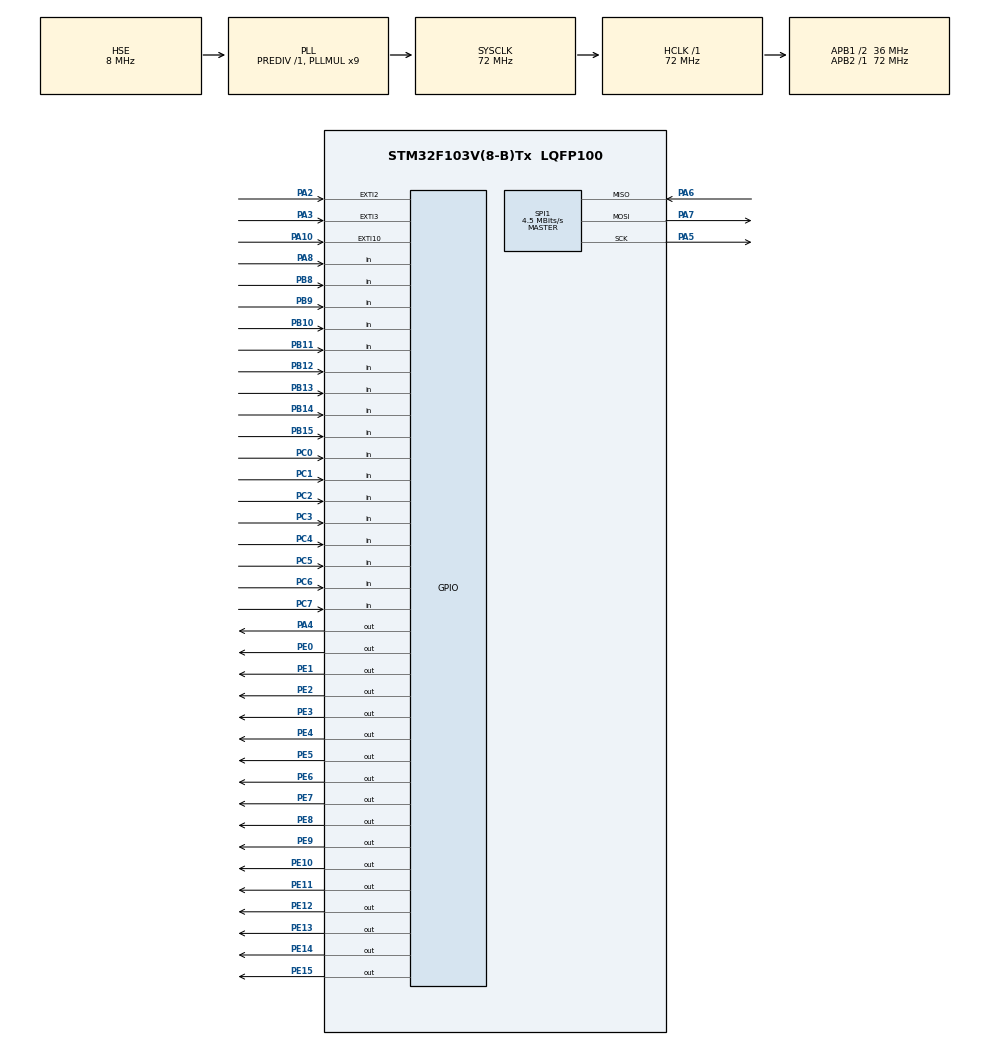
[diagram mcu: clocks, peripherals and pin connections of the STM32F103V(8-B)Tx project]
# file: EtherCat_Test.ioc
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Mcu.Family=STM32F1
Mcu.Name=STM32F103V(8-B)Tx
Mcu.Package=LQFP100
NVIC.EXTI15_10_IRQn=true\:0\:0\:false\:false\:true\:true\:true\:true
NVIC.EXTI2_IRQn=true\:0\:0\:false\:false\:true\:true\:true\:true
NVIC.EXTI3_IRQn=true\:0\:0\:false\:false\:true\:true\:true\:true
NVIC.PriorityGroup=NVIC_PRIORITYGROUP_4
OSC_IN.Mode=HSE-External-Oscillator
OSC_IN.Signal=RCC_OSC_IN
OSC_OUT.Mode=HSE-External-Oscillator
OSC_OUT.Signal=RCC_OSC_OUT
PA10.Signal=GPXTI10
PA13.Mode=Serial_Wire
PA13.Signal=SYS_JTMS-SWDIO
PA14.Mode=Serial_Wire
PA14.Signal=SYS_JTCK-SWCLK
PA2.Signal=GPXTI2
PA3.Signal=GPXTI3
PA4.Signal=GPIO_Output
PA5.Mode=Full_Duplex_Master
PA5.Signal=SPI1_SCK
PA6.Mode=Full_Duplex_Master
PA6.Signal=SPI1_MISO
PA7.Mode=Full_Duplex_Master
PA7.Signal=SPI1_MOSI
PA8.Signal=GPIO_Input
PB10.GPIO_Mode=GPIO_MODE_INPUT
PB10.GPIO_PuPd=GPIO_PULLDOWN
PB10.Signal=GPIO_Input
PB11.GPIO_Mode=GPIO_MODE_INPUT
PB11.GPIO_PuPd=GPIO_PULLDOWN
PB11.Signal=GPIO_Input
PB12.GPIO_Mode=GPIO_MODE_INPUT
PB12.GPIO_PuPd=GPIO_PULLDOWN
PB12.Signal=GPIO_Input
PB13.GPIO_Mode=GPIO_MODE_INPUT
PB13.GPIO_PuPd=GPIO_PULLDOWN
PB13.Signal=GPIO_Input
PB14.GPIO_Mode=GPIO_MODE_INPUT
PB14.GPIO_PuPd=GPIO_PULLDOWN
PB14.Signal=GPIO_Input
PB15.GPIO_Mode=GPIO_MODE_INPUT
PB15.GPIO_PuPd=GPIO_PULLDOWN
PB15.Signal=GPIO_Input
PB8.GPIO_Mode=GPIO_MODE_INPUT
PB8.GPIO_PuPd=GPIO_PULLDOWN
PB8.Signal=GPIO_Input
PB9.GPIO_Mode=GPIO_MODE_INPUT
PB9.GPIO_PuPd=GPIO_PULLDOWN
PB9.Signal=GPIO_Input
PC0.GPIO_Mode=GPIO_MODE_INPUT
PC0.GPIO_PuPd=GPIO_PULLDOWN
PC0.Signal=GPIO_Input
PC1.GPIO_Mode=GPIO_MODE_INPUT
PC1.GPIO_PuPd=GPIO_PULLDOWN
PC1.Signal=GPIO_Input
PC14-OSC32_IN.Mode=LSE-External-Oscillator
PC14-OSC32_IN.Signal=RCC_OSC32_IN
PC15-OSC32_OUT.Mode=LSE-External-Oscillator
PC15-OSC32_OUT.Signal=RCC_OSC32_OUT
PC2.GPIO_Mode=GPIO_MODE_INPUT
PC2.GPIO_PuPd=GPIO_PULLDOWN
PC2.Signal=GPIO_Input
PC3.GPIO_Mode=GPIO_MODE_INPUT
PC3.GPIO_PuPd=GPIO_PULLDOWN
PC3.Signal=GPIO_Input
PC4.GPIO_Mode=GPIO_MODE_INPUT
PC4.GPIO_PuPd=GPIO_PULLDOWN
PC4.Signal=GPIO_Input
PC5.GPIO_Mode=GPIO_MODE_INPUT
PC5.GPIO_PuPd=GPIO_PULLDOWN
PC5.Signal=GPIO_Input
PC6.GPIO_Mode=GPIO_MODE_INPUT
PC6.GPIO_PuPd=GPIO_PULLDOWN
PC6.Signal=GPIO_Input
PC7.GPIO_Mode=GPIO_MODE_INPUT
PC7.GPIO_PuPd=GPIO_PULLDOWN
PC7.Signal=GPIO_Input
PE0.GPIO_ModeDefaultOutputPP=GPIO_MODE_OUTPUT_PP
PE0.GPIO_PuPd=GPIO_NOPULL
PE0.GPIO_Speed=GPIO_SPEED_FREQ_LOW
PE0.PinState=GPIO_PIN_RESET
PE0.Signal=GPIO_Output
PE1.GPIO_ModeDefaultOutputPP=GPIO_MODE_OUTPUT_PP
PE1.GPIO_PuPd=GPIO_NOPULL
PE1.GPIO_Speed=GPIO_SPEED_FREQ_LOW
PE1.PinState=GPIO_PIN_RESET
PE1.Signal=GPIO_Output
PE10.GPIO_ModeDefaultOutputPP=GPIO_MODE_OUTPUT_PP
PE10.GPIO_PuPd=GPIO_NOPULL
PE10.GPIO_Speed=GPIO_SPEED_FREQ_LOW
PE10.PinState=GPIO_PIN_RESET
PE10.Signal=GPIO_Output
PE11.GPIO_ModeDefaultOutputPP=GPIO_MODE_OUTPUT_PP
PE11.GPIO_PuPd=GPIO_NOPULL
PE11.GPIO_Speed=GPIO_SPEED_FREQ_LOW
PE11.PinState=GPIO_PIN_RESET
PE11.Signal=GPIO_Output
PE12.GPIO_ModeDefaultOutputPP=GPIO_MODE_OUTPUT_PP
PE12.GPIO_PuPd=GPIO_NOPULL
PE12.GPIO_Speed=GPIO_SPEED_FREQ_LOW
PE12.PinState=GPIO_PIN_RESET
PE12.Signal=GPIO_Output
PE13.GPIO_ModeDefaultOutputPP=GPIO_MODE_OUTPUT_PP
PE13.GPIO_PuPd=GPIO_NOPULL
PE13.GPIO_Speed=GPIO_SPEED_FREQ_LOW
PE13.PinState=GPIO_PIN_RESET
PE13.Signal=GPIO_Output
PE14.GPIO_ModeDefaultOutputPP=GPIO_MODE_OUTPUT_PP
PE14.GPIO_PuPd=GPIO_NOPULL
PE14.GPIO_Speed=GPIO_SPEED_FREQ_LOW
PE14.PinState=GPIO_PIN_RESET
PE14.Signal=GPIO_Output
PE15.GPIO_ModeDefaultOutputPP=GPIO_MODE_OUTPUT_PP
PE15.GPIO_PuPd=GPIO_NOPULL
PE15.GPIO_Speed=GPIO_SPEED_FREQ_LOW
PE15.PinState=GPIO_PIN_RESET
PE15.Signal=GPIO_Output
PE2.GPIO_ModeDefaultOutputPP=GPIO_MODE_OUTPUT_PP
PE2.GPIO_PuPd=GPIO_NOPULL
PE2.GPIO_Speed=GPIO_SPEED_FREQ_LOW
PE2.PinState=GPIO_PIN_RESET
PE2.Signal=GPIO_Output
PE3.GPIO_ModeDefaultOutputPP=GPIO_MODE_OUTPUT_PP
PE3.GPIO_PuPd=GPIO_NOPULL
PE3.GPIO_Speed=GPIO_SPEED_FREQ_LOW
PE3.PinState=GPIO_PIN_RESET
PE3.Signal=GPIO_Output
PE4.GPIO_ModeDefaultOutputPP=GPIO_MODE_OUTPUT_PP
PE4.GPIO_PuPd=GPIO_NOPULL
PE4.GPIO_Speed=GPIO_SPEED_FREQ_LOW
PE4.PinState=GPIO_PIN_RESET
PE4.Signal=GPIO_Output
PE5.GPIO_ModeDefaultOutputPP=GPIO_MODE_OUTPUT_PP
PE5.GPIO_PuPd=GPIO_NOPULL
PE5.GPIO_Speed=GPIO_SPEED_FREQ_LOW
PE5.PinState=GPIO_PIN_RESET
PE5.Signal=GPIO_Output
PE6.GPIO_ModeDefaultOutputPP=GPIO_MODE_OUTPUT_PP
PE6.GPIO_PuPd=GPIO_NOPULL
PE6.GPIO_Speed=GPIO_SPEED_FREQ_LOW
PE6.PinState=GPIO_PIN_RESET
PE6.Signal=GPIO_Output
PE7.GPIO_ModeDefaultOutputPP=GPIO_MODE_OUTPUT_PP
PE7.GPIO_PuPd=GPIO_NOPULL
PE7.GPIO_Speed=GPIO_SPEED_FREQ_LOW
PE7.PinState=GPIO_PIN_RESET
PE7.Signal=GPIO_Output
PE8.GPIO_ModeDefaultOutputPP=GPIO_MODE_OUTPUT_PP
PE8.GPIO_PuPd=GPIO_NOPULL
PE8.GPIO_Speed=GPIO_SPEED_FREQ_LOW
PE8.PinState=GPIO_PIN_RESET
PE8.Signal=GPIO_Output
PE9.GPIO_ModeDefaultOutputPP=GPIO_MODE_OUTPUT_PP
PE9.GPIO_PuPd=GPIO_NOPULL
PE9.GPIO_Speed=GPIO_SPEED_FREQ_LOW
PE9.PinState=GPIO_PIN_RESET
PE9.Signal=GPIO_Output
ProjectManager.HeapSize=0x200
ProjectManager.StackSize=0x400
ProjectManager.TargetToolchain=MDK-ARM V5.32
RCC.AHBFreq_Value=72000000
RCC.APB1CLKDivider=RCC_HCLK_DIV2
RCC.APB1Freq_Value=36000000
RCC.APB1TimFreq_Value=72000000
RCC.APB2Freq_Value=72000000
RCC.APB2TimFreq_Value=72000000
RCC.HCLKFreq_Value=72000000
RCC.PLLMUL=RCC_PLL_MUL9
RCC.PLLSourceVirtual=RCC_PLLSOURCE_HSE
RCC.SYSCLKFreq_VALUE=72000000
RCC.SYSCLKSource=RCC_SYSCLKSOURCE_PLLCLK
RCC.USBFreq_Value=72000000
SPI1.BaudRatePrescaler=SPI_BAUDRATEPRESCALER_16
SPI1.CLKPhase=SPI_PHASE_2EDGE
SPI1.CLKPolarity=SPI_POLARITY_HIGH
SPI1.CalculateBaudRate=4.5 MBits/s
SPI1.Direction=SPI_DIRECTION_2LINES
SPI1.Mode=SPI_MODE_MASTER
SPI1.VirtualType=VM_MASTER
board=custom

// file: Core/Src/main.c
/* USER CODE BEGIN Header */
/**
  ******************************************************************************
  * @file           : main.c
  * @brief          : Main program body
  ******************************************************************************
  * @attention
  *
  * Copyright (c) 2026 STMicroelectronics.
  * All rights reserved.
  *
  * This software is licensed under terms that can be found in the LICENSE file
  * in the root directory of this software component.
  * If no LICENSE file comes with this software, it is provided AS-IS.
  *
  ******************************************************************************
  */
/* USER CODE END Header */
#include "main.h"
#include "spi.h"
#include "gpio.h"

/* USER CODE BEGIN Includes */
#include "AX58100.h"
#include "app_ethercat.h"
#include "app_coe.h"
/* USER CODE END Includes */

void SystemClock_Config(void);

int main(void)
{

  /* MCU Configuration--------------------------------------------------------*/

  /* Reset of all peripherals, Initializes the Flash interface and the Systick. */
  HAL_Init();

  /* Configure the system clock */
  SystemClock_Config();

  /* Initialize all configured peripherals */
  MX_GPIO_Init();
  MX_SPI1_Init();
  /* USER CODE BEGIN 2 */

  /* 初始化 EtherCAT 状态机, 写 AL Status = Init */
  ECAT_Init();

  /* 初始化 CoE 协议栈 (对象字典) */
  CoE_Init();

  /* 禁用 ESC 看门狗, 防止开发阶段异常复位 */
  ESC_Watchdog_Config();

  /* USER CODE END 2 */

  /* Infinite loop */
  while (1)
  {

    /* USER CODE BEGIN 3 */

    /* ---- 状态机: 两次处理 ACK 握手 ---- */
    ECAT_MainTask();
    ECAT_MainTask();

    /* ---- CoE 邮箱通信: 多次处理以应对主站连续SDO请求 ---- */
    CoE_MainTask();
    CoE_MainTask();
    CoE_MainTask();

    /* ---- 过程数据交换 (OP 态下激活) ---- */
    ECAT_ProcessDataExchange();

    HAL_Delay(5);                 /* 5ms 周期: 给 TwinCAT 足够时间配 SM */
  }
  /* USER CODE END 3 */
}

void SystemClock_Config(void)
{
  RCC_OscInitTypeDef RCC_OscInitStruct = {0};
  RCC_ClkInitTypeDef RCC_ClkInitStruct = {0};

  /** Initializes the RCC Oscillators according to the specified parameters
  * in the RCC_OscInitTypeDef structure.
  */
  RCC_OscInitStruct.OscillatorType = RCC_OSCILLATORTYPE_HSE;
  RCC_OscInitStruct.HSEState = RCC_HSE_ON;
  RCC_OscInitStruct.HSEPredivValue = RCC_HSE_PREDIV_DIV1;
  RCC_OscInitStruct.HSIState = RCC_HSI_ON;
  RCC_OscInitStruct.PLL.PLLState = RCC_PLL_ON;
  RCC_OscInitStruct.PLL.PLLSource = RCC_PLLSOURCE_HSE;
  RCC_OscInitStruct.PLL.PLLMUL = RCC_PLL_MUL9;
  if (HAL_RCC_OscConfig(&RCC_OscInitStruct) != HAL_OK)
  {
    Error_Handler();
  }

  /** Initializes the CPU, AHB and APB buses clocks
  */
  RCC_ClkInitStruct.ClockType = RCC_CLOCKTYPE_HCLK|RCC_CLOCKTYPE_SYSCLK
                              |RCC_CLOCKTYPE_PCLK1|RCC_CLOCKTYPE_PCLK2;
  RCC_ClkInitStruct.SYSCLKSource = RCC_SYSCLKSOURCE_PLLCLK;
  RCC_ClkInitStruct.AHBCLKDivider = RCC_SYSCLK_DIV1;
  RCC_ClkInitStruct.APB1CLKDivider = RCC_HCLK_DIV2;
  RCC_ClkInitStruct.APB2CLKDivider = RCC_HCLK_DIV1;

  if (HAL_RCC_ClockConfig(&RCC_ClkInitStruct, FLASH_LATENCY_2) != HAL_OK)
  {
    Error_Handler();
  }
}

void Error_Handler(void)
{
  __disable_irq();
  while (1)
  {
  }
}
